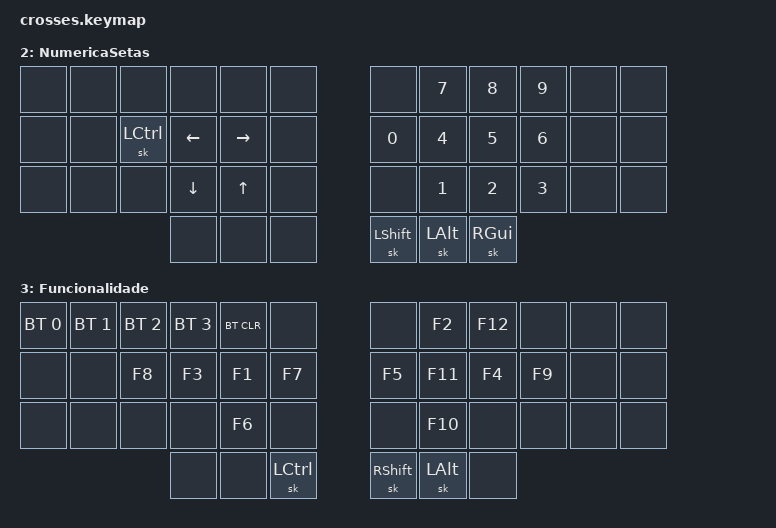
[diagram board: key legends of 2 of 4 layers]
#include <behaviors.dtsi>
#include <dt-bindings/zmk/bt.h>
#include <dt-bindings/zmk/keys.h>
#include <dt-bindings/zmk/pointing.h>

&mt {
    tapping-term-ms = <200>;
    flavor = "balanced";
    quick-tap-ms = <150>;
};

/ {
    behaviors {
        osm_sa: osm_sa {
            compatible = "zmk,behavior-sticky-key";
            #binding-cells = <1>;
            bindings = <&kp>;
        };
    };

    keymap {
        compatible = "zmk,keymap";

        Base {
            bindings = <
&mkp MCLK             &mkp RCLK            &kp Y                 &kp O               &kp X               &mkp LCLK            &kp F             &kp C                  &kp L                      &kp P [...]
&osm_sa (MOD_LSFT | MOD_LALT) &kp H        &kp I                 &kp E               &kp A               &kp U                &kp D             &kp S                  &kp T                      &kp N [...]
&to 2                 &kp Z                &sl 3                 &kp J               &kp K               &kp DELETE           &kp W             &kp G                  &kp M                      &kp B [...]
                                                        &sl 1                &lt 2 ESCAPE       &mt LEFT_CONTROL SPACE  &mt RIGHT_SHIFT BACKSPACE  &mt LEFT_ALT ENTER    &sk LEFT_GUI
            >;
        };

        Pontuacao {
            bindings = <
&none             &kp LS(N3)           &kp LS(N6)            &kp LS(N4)          &kp SQT             &kp LS(N5)           &kp LS(GRAVE)     &kp LS(N2)             &kp LS(EQUAL)              &kp SLASH [...]
&kp LEFT_BRACKET  &kp MINUS            &kp LS(LEFT_BRACKET)  &kp LS(N9)          &kp LS(SQT)         &kp COMMA            &kp LS(N1)        &kp COMMA              &kp DOT                    &kp SEMICO[...]
&none             &kp LS(MINUS)        &kp LS(RIGHT_BRACKET) &kp LS(N0)          &kp GRAVE           &kp LS(DOT)          &kp LS(SLASH)     &kp LS(SEMICOLON)      &kp LS(BACKSLASH)          &kp LS(N8)[...]
                                                        &none                &none               &kp LEFT_CONTROL      &mo 0                    &kp LEFT_ALT          &none
            >;
        };

        NumericaSetas {
            bindings = <
&none  &none  &none              &none            &none             &none  &none          &kp NUMBER_7  &kp NUMBER_8  &kp NUMBER_9  &none  &none
&none  &none  &sk LEFT_CONTROL   &kp LEFT_ARROW   &kp RIGHT_ARROW   &none  &kp NUMBER_0   &kp NUMBER_4  &kp NUMBER_5  &kp NUMBER_6  &none  &none
&none  &none  &none              &kp DOWN_ARROW   &kp UP_ARROW      &none  &none          &kp NUMBER_1  &kp NUMBER_2  &kp NUMBER_3  &none  &none
                                  &none            &none             &none  &sk LEFT_SHIFT &sk LEFT_ALT  &sk RIGHT_GUI
            >;
        };

        Funcionalidade {
            bindings = <
&bt BT_SEL 0  &bt BT_SEL 1  &bt BT_SEL 2  &bt BT_SEL 3  &bt BT_CLR  &none  &none    &kp F2   &kp F12  &none   &none  &none
&none         &none         &kp F8        &kp F3        &kp F1      &kp F7  &kp F5   &kp F11  &kp F4   &kp F9   &none  &none
&none         &none         &none         &none         &kp F6      &none   &none    &kp F10  &none    &none    &none  &none
                              &none        &none         &sk LEFT_CONTROL  &sk RIGHT_SHIFT  &sk LEFT_ALT  &none
            >;
        };
    };
};
